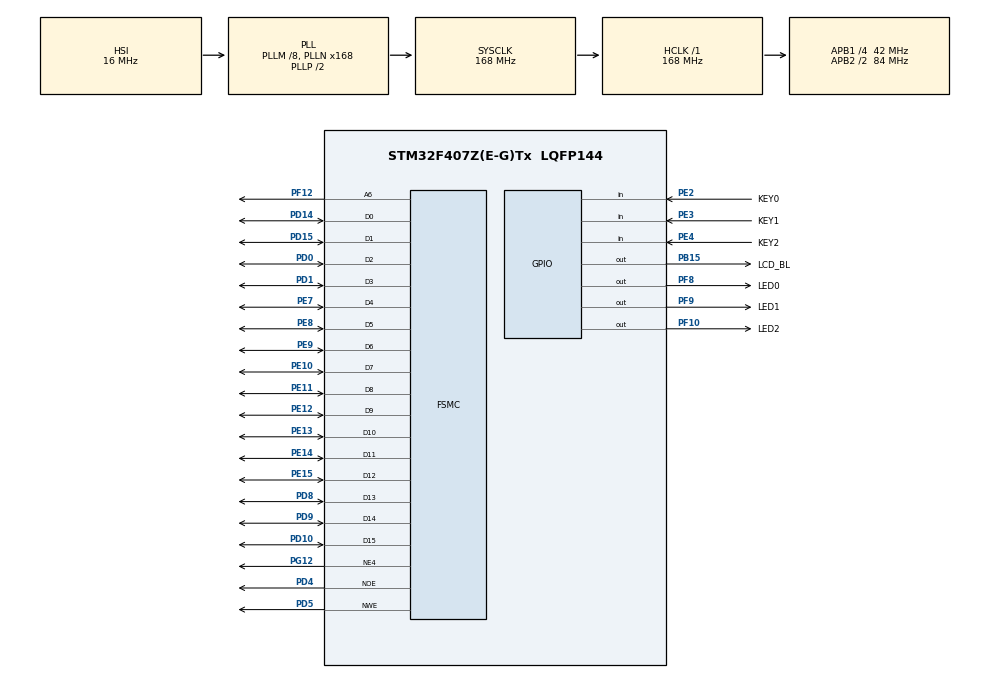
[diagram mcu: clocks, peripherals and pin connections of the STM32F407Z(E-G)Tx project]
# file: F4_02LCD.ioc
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Mcu.Family=STM32F4
FSMC.AddressSetupTime1=0x0f
PE7.GPIO_PuPd=GPIO_PULLUP
PH0-OSC_IN.Signal=RCC_OSC_IN
PF10.GPIO_ModeDefaultOutputPP=GPIO_MODE_OUTPUT_PP
RCC.CortexFreq_Value=168000000
SH.FSMC_D1_DA1.0=FSMC_D1,16b-d1
SH.FSMC_A6.0=FSMC_A6,A6_1
SH.FSMC_NWE.0=FSMC_NWE,Lcd1
PE8.GPIO_PuPd=GPIO_PULLUP
SH.FSMC_D0_DA0.0=FSMC_D0,16b-d1
PE10.GPIO_PuPd=GPIO_PULLUP
PF9.GPIO_Speed=GPIO_SPEED_FREQ_VERY_HIGH
PD10.GPIO_PuPd=GPIO_PULLUP
FSMC.ExtendedBusTurnAroundDuration1=0
PD8.GPIO_PuPd=GPIO_PULLUP
PF10.GPIO_PuPd=GPIO_PULLUP
PB15.Signal=GPIO_Output
PF8.PinState=GPIO_PIN_RESET
RCC.SYSCLKSource=RCC_SYSCLKSOURCE_PLLCLK
ProjectManager.StackSize=0x400
VP_TIM7_VS_ClockSourceINT.Mode=Enable_Timer
PE11.GPIO_PuPd=GPIO_PULLUP
RCC.HCLKFreq_Value=168000000
PD4.Signal=FSMC_NOE
RCC.APB2TimFreq_Value=168000000
PF12.Signal=FSMC_A6
PD0.Signal=FSMC_D2_DA2
TIM7.Period=1
PD8.Signal=FSMC_D13_DA13
PF10.GPIO_Label=LED2
RCC.AHBFreq_Value=168000000
PH0-OSC_IN.Mode=HSE-External-Oscillator
RCC.HSE_VALUE=8000000
PE13.GPIO_PuPd=GPIO_PULLUP
PE13.Signal=FSMC_D10_DA10
SH.FSMC_D14_DA14.0=FSMC_D14,16b-d1
SH.FSMC_D10_DA10.0=FSMC_D10,16b-d1
PF8.GPIO_ModeDefaultOutputPP=GPIO_MODE_OUTPUT_PP
PF8.GPIO_PuPd=GPIO_PULLUP
PE9.Signal=FSMC_D6_DA6
PA14.Mode=Serial_Wire
SH.FSMC_D6_DA6.0=FSMC_D6,16b-d1
PE4.GPIO_Label=KEY2
PE2.Signal=GPIO_Input
PD14.GPIO_PuPd=GPIO_PULLUP
FSMC.BusTurnAroundDuration1=0
PE10.Signal=FSMC_D7_DA7
PE4.Signal=GPIO_Input
SH.FSMC_D5_DA5.0=FSMC_D5,16b-d1
SH.FSMC_D4_DA4.0=FSMC_D4,16b-d1
PH1-OSC_OUT.Mode=HSE-External-Oscillator
Mcu.Package=LQFP144
PB15.GPIO_PuPd=GPIO_PULLUP
PD15.GPIO_PuPd=GPIO_PULLUP
SH.FSMC_D13_DA13.0=FSMC_D13,16b-d1
PF8.Signal=GPIO_Output
RCC.APB2CLKDivider=RCC_HCLK_DIV2
SH.FSMC_D3_DA3.0=FSMC_D3,16b-d1
PG12.GPIO_PuPd=GPIO_PULLUP
RCC.APB1TimFreq_Value=84000000
SH.FSMC_D2_DA2.0=FSMC_D2,16b-d1
PE7.Signal=FSMC_D4_DA4
PF9.GPIO_PuPd=GPIO_PULLUP
PD9.GPIO_PuPd=GPIO_PULLUP
PE2.GPIO_Label=KEY0
PD15.Signal=FSMC_D1_DA1
PE12.GPIO_PuPd=GPIO_PULLUP
PG12.Signal=FSMC_NE4
FSMC.ExtendedAddressSetupTime1=9
SH.FSMC_D12_DA12.0=FSMC_D12,16b-d1
FSMC.ExtendedMode1=FSMC_EXTENDED_MODE_ENABLE
PF10.GPIO_Speed=GPIO_SPEED_FREQ_VERY_HIGH
PD1.Signal=FSMC_D3_DA3
SH.FSMC_D9_DA9.0=FSMC_D9,16b-d1
PD9.Signal=FSMC_D14_DA14
PD5.Signal=FSMC_NWE
PD1.GPIO_PuPd=GPIO_PULLUP
RCC.APB1CLKDivider=RCC_HCLK_DIV4
SH.FSMC_D8_DA8.0=FSMC_D8,16b-d1
PF8.GPIO_Label=LED0
PD10.Signal=FSMC_D15_DA15
PA13.Signal=SYS_JTMS-SWDIO
PD4.GPIO_PuPd=GPIO_PULLUP
ProjectManager.TargetToolchain=STM32CubeIDE
FSMC.DataSetupTime1=60
PF9.PinState=GPIO_PIN_RESET
PF9.GPIO_Label=LED1
PE11.Signal=FSMC_D8_DA8
RCC.LSE_VALUE=32768
PE2.GPIO_PuPd=GPIO_PULLUP
SH.FSMC_D7_DA7.0=FSMC_D7,16b-d1
FSMC.ExtendedDataSetupTime1=8
TIM7.Prescaler=83
board=custom
PG12.Mode=NorPsramChipSelect4_1
RCC.VCOOutputFreq_Value=336000000
RCC.APB2Freq_Value=84000000
PE14.Signal=FSMC_D11_DA11
PE15.Signal=FSMC_D12_DA12
PB15.GPIO_Label=LCD_BL
PE8.Signal=FSMC_D5_DA5
PF10.Signal=GPIO_Output
PB15.GPIO_Speed=GPIO_SPEED_FREQ_MEDIUM
PH1-OSC_OUT.Signal=RCC_OSC_OUT
PE3.GPIO_PuPd=GPIO_PULLUP
PD5.GPIO_PuPd=GPIO_PULLUP
PE14.GPIO_PuPd=GPIO_PULLUP
PA13.Mode=Serial_Wire
Mcu.Name=STM32F407Z(E-G)Tx
PE12.Signal=FSMC_D9_DA9
PE4.GPIO_PuPd=GPIO_PULLUP
PD14.Signal=FSMC_D0_DA0
RCC.48MHZClocksFreq_Value=84000000
RCC.SYSCLKFreq_VALUE=168000000
SH.FSMC_D15_DA15.0=FSMC_D15,16b-d1
PA14.Signal=SYS_JTCK-SWCLK
PE15.GPIO_PuPd=GPIO_PULLUP
ProjectManager.HeapSize=0x200
SH.FSMC_D11_DA11.0=FSMC_D11,16b-d1
PD0.GPIO_PuPd=GPIO_PULLUP
SH.FSMC_NOE.0=FSMC_NOE,Lcd1
PF9.Signal=GPIO_Output
RCC.HSI_VALUE=16000000
PF9.GPIO_ModeDefaultOutputPP=GPIO_MODE_OUTPUT_PP
NVIC.PriorityGroup=NVIC_PRIORITYGROUP_4
RCC.PLLM=8
RCC.PLLN=168
PF8.GPIO_Speed=GPIO_SPEED_FREQ_VERY_HIGH
PE3.Signal=GPIO_Input
PF12.GPIO_PuPd=GPIO_PULLUP
PE3.GPIO_Label=KEY1
RCC.APB1Freq_Value=42000000
PF10.PinState=GPIO_PIN_RESET
PE9.GPIO_PuPd=GPIO_PULLUP

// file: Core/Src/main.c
/* USER CODE BEGIN Header */
/**
  ******************************************************************************
  * @file           : main.c
  * @brief          : Main program body
  ******************************************************************************
  * @attention
  *
  * <h2><center>&copy; Copyright (c) 2021 STMicroelectronics.
  * All rights reserved.</center></h2>
  *
  * This software component is licensed by ST under BSD 3-Clause license,
  * the "License"; You may not use this file except in compliance with the
  * License. You may obtain a copy of the License at:
  *                        opensource.org/licenses/BSD-3-Clause
  *
  ******************************************************************************
  */
/* USER CODE END Header */
#include "main.h"
#include "tim.h"
#include "gpio.h"
#include "fsmc.h"

/* USER CODE BEGIN Includes */
#include "lcd.h"
#include "base.h"
/* USER CODE END Includes */

void SystemClock_Config(void);

int main(void)
{

  /* MCU Configuration--------------------------------------------------------*/

  /* Reset of all peripherals, Initializes the Flash interface and the Systick. */
  HAL_Init();

  /* Configure the system clock */
  SystemClock_Config();

  /* Initialize all configured peripherals */
  MX_GPIO_Init();
  MX_FSMC_Init();
  MX_TIM7_Init();
  /* USER CODE BEGIN 2 */
  delay_init(168);
  LCD_Init();
  LCD_ShowString(30,40,210,24,24,(uint8_t *)"MINI STM32F4");
  LCD_ShowString(30,70,200,16,16,(uint8_t *)"TFTLCD TEST");
  LCD_ShowString(30,90,200,16,16,(uint8_t *)"ATOM@ALIENTEK");
  LCD_ShowString(30,110,200,16,16,(uint8_t *)"The First Test");
  LCD_ShowString(30,130,200,12,12,(uint8_t *)"2021/4/8");

  /* USER CODE END 2 */

  /* Infinite loop */
  while (1)
  {

  }
}

void SystemClock_Config(void)
{
  RCC_OscInitTypeDef RCC_OscInitStruct = {0};
  RCC_ClkInitTypeDef RCC_ClkInitStruct = {0};

  /** Configure the main internal regulator output voltage
  */
  __HAL_RCC_PWR_CLK_ENABLE();
  __HAL_PWR_VOLTAGESCALING_CONFIG(PWR_REGULATOR_VOLTAGE_SCALE1);
  /** Initializes the RCC Oscillators according to the specified parameters
  * in the RCC_OscInitTypeDef structure.
  */
  RCC_OscInitStruct.OscillatorType = RCC_OSCILLATORTYPE_HSI;
  RCC_OscInitStruct.HSIState = RCC_HSI_ON;
  RCC_OscInitStruct.HSICalibrationValue = RCC_HSICALIBRATION_DEFAULT;
  RCC_OscInitStruct.PLL.PLLState = RCC_PLL_ON;
  RCC_OscInitStruct.PLL.PLLSource = RCC_PLLSOURCE_HSI;
  RCC_OscInitStruct.PLL.PLLM = 8;
  RCC_OscInitStruct.PLL.PLLN = 168;
  RCC_OscInitStruct.PLL.PLLP = RCC_PLLP_DIV2;
  RCC_OscInitStruct.PLL.PLLQ = 4;
  if (HAL_RCC_OscConfig(&RCC_OscInitStruct) != HAL_OK)
  {
    Error_Handler();
  }
  /** Initializes the CPU, AHB and APB buses clocks
  */
  RCC_ClkInitStruct.ClockType = RCC_CLOCKTYPE_HCLK|RCC_CLOCKTYPE_SYSCLK
                              |RCC_CLOCKTYPE_PCLK1|RCC_CLOCKTYPE_PCLK2;
  RCC_ClkInitStruct.SYSCLKSource = RCC_SYSCLKSOURCE_PLLCLK;
  RCC_ClkInitStruct.AHBCLKDivider = RCC_SYSCLK_DIV1;
  RCC_ClkInitStruct.APB1CLKDivider = RCC_HCLK_DIV4;
  RCC_ClkInitStruct.APB2CLKDivider = RCC_HCLK_DIV2;

  if (HAL_RCC_ClockConfig(&RCC_ClkInitStruct, FLASH_LATENCY_5) != HAL_OK)
  {
    Error_Handler();
  }
}

void Error_Handler(void)
{
  __disable_irq();
  while (1)
  {
  }
}

/************************ (C) COPYRIGHT STMicroelectronics *****END OF FILE****/
